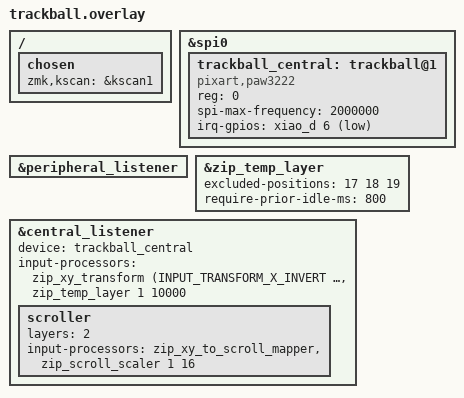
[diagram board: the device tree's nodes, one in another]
/ {
    chosen {
        zmk,kscan = &kscan1;
    };
};

&spi0 {
    status = "okay";

    trackball_central: trackball@1 {
        status = "okay";
        compatible = "pixart,paw3222";
        reg = <0>;
        spi-max-frequency = <2000000>;
        irq-gpios = <&xiao_d 6 (GPIO_ACTIVE_LOW | GPIO_PULL_UP)>;
    };
};

&peripheral_listener {
    status = "okay";
};

&zip_temp_layer {
    excluded-positions = <
        17 // J
        18 // K
        19 // L
    >;

    require-prior-idle-ms = <800>;
};

&central_listener {
    status = "okay";
    device = <&trackball_central>;
    input-processors = 
        <&zip_xy_transform (INPUT_TRANSFORM_X_INVERT | INPUT_TRANSFORM_Y_INVERT)>,
        <&zip_temp_layer 1 10000>;

    scroller {
        layers = <2>;
        input-processors = 
            <&zip_xy_to_scroll_mapper>,
            <&zip_scroll_scaler 1 16>;
    };
};
